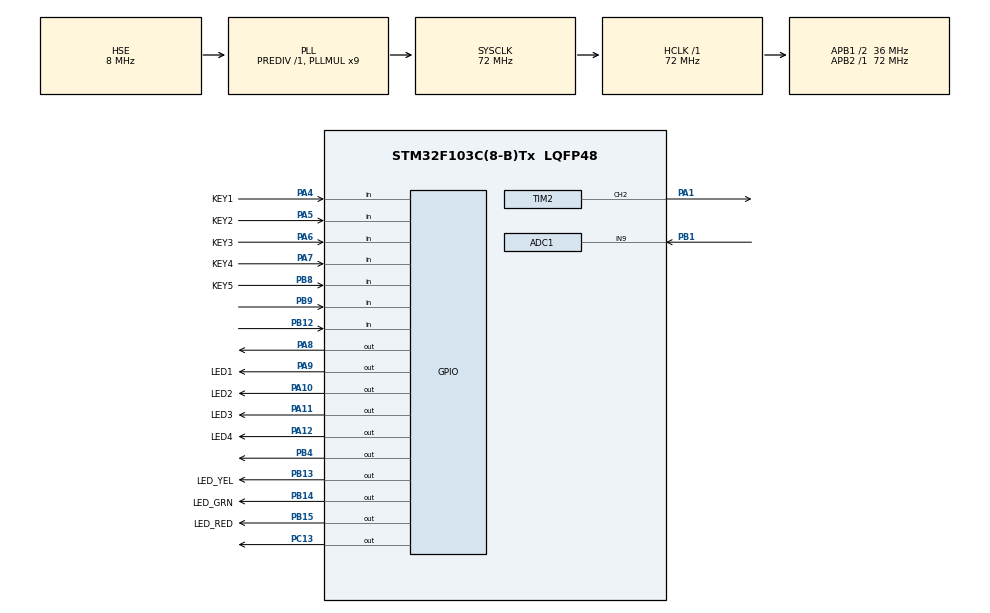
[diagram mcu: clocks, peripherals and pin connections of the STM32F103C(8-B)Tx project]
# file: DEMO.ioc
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ADC1.Channel-0\#ChannelRegularConversion=ADC_CHANNEL_9
ADC1.ContinuousConvMode=ENABLE
ADC1.NbrOfConversionFlag=1
ADC1.Rank-0\#ChannelRegularConversion=1
ADC1.SamplingTime-0\#ChannelRegularConversion=ADC_SAMPLETIME_1CYCLE_5
ADC1.master=1
Dma.ADC1.0.Direction=DMA_PERIPH_TO_MEMORY
Dma.ADC1.0.Instance=DMA1_Channel1
Dma.ADC1.0.MemDataAlignment=DMA_MDATAALIGN_WORD
Dma.ADC1.0.MemInc=DMA_MINC_ENABLE
Dma.ADC1.0.Mode=DMA_CIRCULAR
Dma.ADC1.0.PeriphDataAlignment=DMA_PDATAALIGN_WORD
Dma.ADC1.0.PeriphInc=DMA_PINC_DISABLE
Dma.ADC1.0.Priority=DMA_PRIORITY_MEDIUM
Dma.Request0=ADC1
Mcu.Family=STM32F1
Mcu.Name=STM32F103C(8-B)Tx
Mcu.Package=LQFP48
NVIC.ADC1_2_IRQn=true\:2\:0\:true\:false\:true\:true\:true\:true
NVIC.DMA1_Channel1_IRQn=true\:0\:0\:false\:false\:true\:false\:true\:true
NVIC.PriorityGroup=NVIC_PRIORITYGROUP_4
PA1.Signal=S_TIM2_CH2
PA10.GPIO_Label=LED2
PA10.GPIO_ModeDefaultOutputPP=GPIO_MODE_OUTPUT_PP
PA10.GPIO_PuPd=GPIO_NOPULL
PA10.GPIO_Speed=GPIO_SPEED_FREQ_LOW
PA10.PinState=GPIO_PIN_SET
PA10.Signal=GPIO_Output
PA11.GPIO_Label=LED3
PA11.GPIO_ModeDefaultOutputPP=GPIO_MODE_OUTPUT_PP
PA11.GPIO_PuPd=GPIO_NOPULL
PA11.GPIO_Speed=GPIO_SPEED_FREQ_LOW
PA11.PinState=GPIO_PIN_SET
PA11.Signal=GPIO_Output
PA12.GPIO_Label=LED4
PA12.GPIO_ModeDefaultOutputPP=GPIO_MODE_OUTPUT_PP
PA12.GPIO_PuPd=GPIO_NOPULL
PA12.GPIO_Speed=GPIO_SPEED_FREQ_LOW
PA12.PinState=GPIO_PIN_SET
PA12.Signal=GPIO_Output
PA13.Mode=Serial_Wire
PA13.Signal=SYS_JTMS-SWDIO
PA14.Mode=Serial_Wire
PA14.Signal=SYS_JTCK-SWCLK
PA4.GPIO_Label=KEY1
PA4.GPIO_Mode=GPIO_MODE_INPUT
PA4.GPIO_PuPd=GPIO_PULLUP
PA4.Signal=GPIO_Input
PA5.GPIO_Label=KEY2
PA5.GPIO_Mode=GPIO_MODE_INPUT
PA5.GPIO_PuPd=GPIO_PULLUP
PA5.Signal=GPIO_Input
PA6.GPIO_Label=KEY3
PA6.GPIO_Mode=GPIO_MODE_INPUT
PA6.GPIO_PuPd=GPIO_PULLUP
PA6.Signal=GPIO_Input
PA7.GPIO_Label=KEY4
PA7.GPIO_Mode=GPIO_MODE_INPUT
PA7.GPIO_PuPd=GPIO_PULLUP
PA7.Signal=GPIO_Input
PA8.Signal=GPIO_Output
PA9.GPIO_Label=LED1
PA9.GPIO_ModeDefaultOutputPP=GPIO_MODE_OUTPUT_PP
PA9.GPIO_PuPd=GPIO_NOPULL
PA9.GPIO_Speed=GPIO_SPEED_FREQ_LOW
PA9.PinState=GPIO_PIN_SET
PA9.Signal=GPIO_Output
PB1.Signal=ADCx_IN9
PB12.GPIO_PuPd=GPIO_PULLDOWN
PB12.Signal=GPIO_Input
PB13.GPIO_Label=LED_YEL
PB13.GPIO_ModeDefaultOutputPP=GPIO_MODE_OUTPUT_PP
PB13.GPIO_PuPd=GPIO_NOPULL
PB13.GPIO_Speed=GPIO_SPEED_FREQ_LOW
PB13.PinState=GPIO_PIN_SET
PB13.Signal=GPIO_Output
PB14.GPIO_Label=LED_GRN
PB14.GPIO_ModeDefaultOutputPP=GPIO_MODE_OUTPUT_PP
PB14.GPIO_PuPd=GPIO_NOPULL
PB14.GPIO_Speed=GPIO_SPEED_FREQ_LOW
PB14.PinState=GPIO_PIN_SET
PB14.Signal=GPIO_Output
PB15.GPIO_Label=LED_RED
PB15.GPIO_ModeDefaultOutputPP=GPIO_MODE_OUTPUT_PP
PB15.GPIO_PuPd=GPIO_NOPULL
PB15.GPIO_Speed=GPIO_SPEED_FREQ_LOW
PB15.PinState=GPIO_PIN_SET
PB15.Signal=GPIO_Output
PB4.GPIO_ModeDefaultOutputPP=GPIO_MODE_OUTPUT_PP
PB4.GPIO_PuPd=GPIO_NOPULL
PB4.PinState=GPIO_PIN_SET
PB4.Signal=GPIO_Output
PB8.GPIO_Label=KEY5
PB8.GPIO_Mode=GPIO_MODE_INPUT
PB8.GPIO_PuPd=GPIO_PULLUP
PB8.Signal=GPIO_Input
PB9.Signal=GPIO_Input
PC13-TAMPER-RTC.GPIO_PuPd=GPIO_PULLUP
PC13-TAMPER-RTC.Signal=GPIO_Output
PD0-OSC_IN.Mode=HSE-External-Oscillator
PD0-OSC_IN.Signal=RCC_OSC_IN
PD1-OSC_OUT.Mode=HSE-External-Oscillator
PD1-OSC_OUT.Signal=RCC_OSC_OUT
ProjectManager.HeapSize=0x200
ProjectManager.StackSize=0x400
ProjectManager.TargetToolchain=MDK-ARM V5.32
RCC.ADCPresc=RCC_ADCPCLK2_DIV6
RCC.AHBFreq_Value=72000000
RCC.APB1CLKDivider=RCC_HCLK_DIV2
RCC.APB1Freq_Value=36000000
RCC.APB1TimFreq_Value=72000000
RCC.APB2Freq_Value=72000000
RCC.APB2TimFreq_Value=72000000
RCC.HCLKFreq_Value=72000000
RCC.PLLMUL=RCC_PLL_MUL9
RCC.PLLSourceVirtual=RCC_PLLSOURCE_HSE
RCC.SYSCLKFreq_VALUE=72000000
RCC.SYSCLKSource=RCC_SYSCLKSOURCE_PLLCLK
RCC.USBFreq_Value=72000000
SH.ADCx_IN9.0=ADC1_IN9,IN9
SH.S_TIM2_CH2.0=TIM2_CH2,PWM Generation2 CH2
TIM2.AutoReloadPreload=TIM_AUTORELOAD_PRELOAD_ENABLE
TIM2.Channel-PWM\ Generation2\ CH2=TIM_CHANNEL_2
TIM2.Period=2000
TIM2.Prescaler=720-1
TIM2.Pulse-PWM\ Generation2\ CH2=1000-1
VP_TIM2_VS_ClockSourceINT.Mode=Internal
board=custom

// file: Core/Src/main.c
/* USER CODE BEGIN Header */
/**
  ******************************************************************************
  * @file           : main.c
  * @brief          : Main program body
  ******************************************************************************
  * @attention
  *
  * Copyright (c) 2024 STMicroelectronics.
  * All rights reserved.
  *
  * This software is licensed under terms that can be found in the LICENSE file
  * in the root directory of this software component.
  * If no LICENSE file comes with this software, it is provided AS-IS.
  *
  ******************************************************************************
  */
/* USER CODE END Header */
#include "main.h"
#include "adc.h"
#include "dma.h"
#include "tim.h"
#include "gpio.h"

/* USER CODE BEGIN Includes */
#include "bsp_system.h"

/* USER CODE END Includes */

void SystemClock_Config(void);

int main(void)
{

  /* MCU Configuration--------------------------------------------------------*/

  /* Reset of all peripherals, Initializes the Flash interface and the Systick. */
  HAL_Init();

  /* Configure the system clock */
  SystemClock_Config();

  /* Initialize all configured peripherals */
  MX_GPIO_Init();
  MX_DMA_Init();
  MX_TIM2_Init();
  MX_ADC1_Init();
  /* USER CODE BEGIN 2 */
  OLED_Init();
  OLED_Clear();
  sys_stm32_clock_init(RCC_PLL_MUL9);
  delay_init(72);
  BODY_HW_Init();
  scheduler_init();
  dht11_init();/* DHT11初始化 */
  delay_ms(200);
  HAL_TIM_PWM_Start(&htim2,TIM_CHANNEL_2);
  OLED_Clear();
  /* USER CODE END 2 */

  /* Infinite loop */
  while (1)
  {

    /* USER CODE BEGIN 3 */
      DHT11_proc();
      HCSR501_proc();
      scheduler_run();

  }
  /* USER CODE END 3 */
}

void SystemClock_Config(void)
{
  RCC_OscInitTypeDef RCC_OscInitStruct = {0};
  RCC_ClkInitTypeDef RCC_ClkInitStruct = {0};
  RCC_PeriphCLKInitTypeDef PeriphClkInit = {0};

  /** Initializes the RCC Oscillators according to the specified parameters
  * in the RCC_OscInitTypeDef structure.
  */
  RCC_OscInitStruct.OscillatorType = RCC_OSCILLATORTYPE_HSE;
  RCC_OscInitStruct.HSEState = RCC_HSE_ON;
  RCC_OscInitStruct.HSEPredivValue = RCC_HSE_PREDIV_DIV1;
  RCC_OscInitStruct.HSIState = RCC_HSI_ON;
  RCC_OscInitStruct.PLL.PLLState = RCC_PLL_ON;
  RCC_OscInitStruct.PLL.PLLSource = RCC_PLLSOURCE_HSE;
  RCC_OscInitStruct.PLL.PLLMUL = RCC_PLL_MUL9;
  if (HAL_RCC_OscConfig(&RCC_OscInitStruct) != HAL_OK)
  {
    Error_Handler();
  }

  /** Initializes the CPU, AHB and APB buses clocks
  */
  RCC_ClkInitStruct.ClockType = RCC_CLOCKTYPE_HCLK|RCC_CLOCKTYPE_SYSCLK
                              |RCC_CLOCKTYPE_PCLK1|RCC_CLOCKTYPE_PCLK2;
  RCC_ClkInitStruct.SYSCLKSource = RCC_SYSCLKSOURCE_PLLCLK;
  RCC_ClkInitStruct.AHBCLKDivider = RCC_SYSCLK_DIV1;
  RCC_ClkInitStruct.APB1CLKDivider = RCC_HCLK_DIV2;
  RCC_ClkInitStruct.APB2CLKDivider = RCC_HCLK_DIV1;

  if (HAL_RCC_ClockConfig(&RCC_ClkInitStruct, FLASH_LATENCY_2) != HAL_OK)
  {
    Error_Handler();
  }
  PeriphClkInit.PeriphClockSelection = RCC_PERIPHCLK_ADC;
  PeriphClkInit.AdcClockSelection = RCC_ADCPCLK2_DIV6;
  if (HAL_RCCEx_PeriphCLKConfig(&PeriphClkInit) != HAL_OK)
  {
    Error_Handler();
  }
}

void Error_Handler(void)
{
  __disable_irq();
  while (1)
  {
  }
}
